# GD32E50x_CL register map
File version: 1.0
CPU: CM33 r0p4, little endian, MPU, FPU, 4 interrupt priority bits
Registers are 32-bit, read-write, reset 0x0 unless marked. A register's access mark holds for its fields unless they carry their own. Offsets are from the block's base; [hi:lo] are bit positions; {n}, {i} and the like mark numbered series.

## SHRTIMER_COMMON — SHRTIMER Common registers
Base 0x40017780
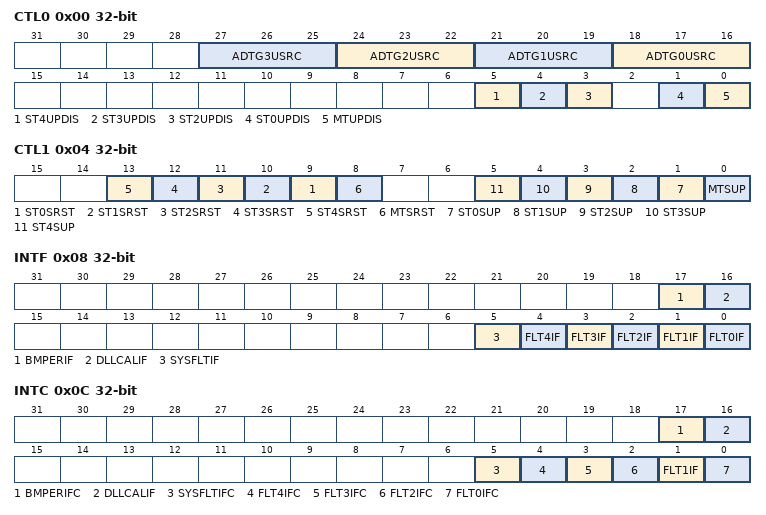
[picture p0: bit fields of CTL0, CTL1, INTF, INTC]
0x00 CTL0 — SHRTIMER control register 0
  [3n+18:3n+16] ADTG{n}USRC (n=0..3) — SHRTIMER_ADCTRIG{n} update source
  [5] ST4UPDIS — Slave_TIMER4 update disable
  [4] ST3UPDIS — Slave_TIMER3 update disable
  [3] ST2UPDIS — Slave_TIMER2 update disable
  [1] ST0UPDIS — Slave_TIMER0 update disable
  [0] MTUPDIS — Master_TIMER update disable
0x04 CTL1 — SHRTIMER control register 1
  [n+9] ST{n}SRST (n=0..4) — Slave_TIMER{n} software reset
  [8] MTSRST — Master_TIMER software reset
  [n+1] ST{n}SUP (n=0..4) — Slave_TIMER{n} software update
  [0] MTSUP — Master_TIMER software update
0x08 INTF ro — SHRTIMER interrupt flag register
  [17] BMPERIF — Bunch mode period interrupt flag
  [16] DLLCALIF — DLL calibration completed interrupt flag
  [5] SYSFLTIF — System fault interrupt flag
  [n] FLT{n}IF (n=0..4) — Fault {n} interrupt flag
0x0C INTC wo — SHRTIMER interrupt flag clear register
  [17] BMPERIFC — Clear bunch mode period interrupt flag
  [16] DLLCALIF — Clear DLL calibration completed interrupt flag
  [5] SYSFLTIFC — Clear system fault interrupt flag
  [4] FLT4IFC — Clear fault 4 interrupt flag
  [3] FLT3IFC — Clear fault 3 interrupt flag
  [2] FLT2IFC — Clear fault 2 interrupt flag
  [1] FLT1IF — Fault 1 interrupt flag
  [0] FLT0IFC — Fault 0 interrupt flag
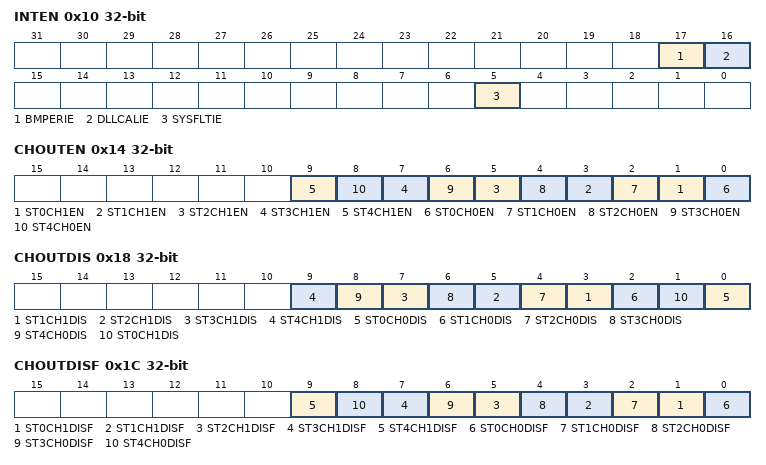
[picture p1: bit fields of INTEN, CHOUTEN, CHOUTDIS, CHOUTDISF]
0x10 INTEN — SHRTIMER interrupt enable register
  [17] BMPERIE — Bunch mode period interrupt enable
  [16] DLLCALIE — DLL calibration completed interrupt enable
  [5] SYSFLTIE — System fault interrupt enable
0x14 CHOUTEN — SHRTIMER channel output enable register
  [2n+1] ST{n}CH1EN (n=0..4) — Slave_TIMER{n} channel 1 output (ST{n}CH1_O) enable
  [2n] ST{n}CH0EN (n=0..4) — Slave_TIMER{n} channel 0 output (ST{n}CH0_O) enable
0x18 CHOUTDIS wo — SHRTIMER channel output disable register
  [2n+1] ST{n}CH1DIS (n=1..4) — Slave_TIMER{n} channel 1 output (ST{n}CH1_O) disable
  [2n] ST{n}CH0DIS (n=0..4) — Slave_TIMER{n} channel 0 output (ST{n}CH0_O) disable
  [1] ST0CH1DIS — Slave_TIMER0 channel 1 output (ST4CH0_O) disable
0x1C CHOUTDISF ro — SHRTIMER channel output disable flag register
  [2n+1] ST{n}CH1DISF (n=0..4) — Slave_TIMER{n} channel 1 output (ST{n}CH1_O) disable flag
  [2n] ST{n}CH0DISF (n=0..4) — Slave_TIMER{n} channel 0 output (ST{n}CH0_O) disable flag
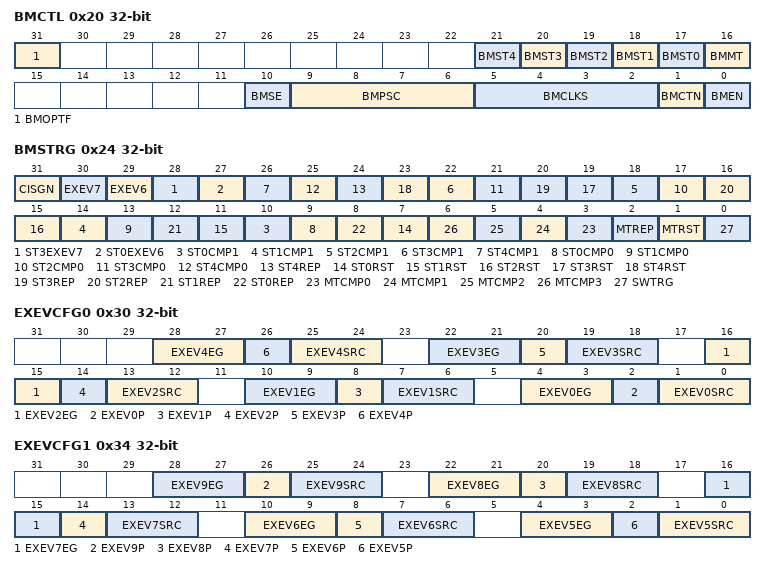
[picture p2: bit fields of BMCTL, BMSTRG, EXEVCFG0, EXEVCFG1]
0x20 BMCTL — SHRTIMER bunch mode control register
  [31] BMOPTF — Bunch mode operating flag
  [n+17] BMST{n} (n=0..4) — Slave_TIMER{n} bunch mode
  [16] BMMT — Master_TIMER bunch mode
  [10] BMSE — Bunch mode shadow enable
  [9:6] BMPSC — Bunch mode clock division
  [5:2] BMCLKS — Bunch mode clock source
  [1] BMCTN — Continuous mode in bunch mode
  [0] BMEN — Bunch mode enable
0x24 BMSTRG — SHRTIMER bunch mode start trigger register
  [31] CISGN — Chip internal signal triggers bunch mode operation
  [30] EXEV7 — External event 7 triggers bunch mode operation
  [29] EXEV6 — External event 6 triggers bunch mode operation
  [28] ST3EXEV7 — Slave_TIMER3 period event following external event 7 triggers bunch mode operation
  [27] ST0EXEV6 — Slave_TIMER0 period event following external event 6 triggers bunch mode operation
  [4n+10] ST{n}CMP1 (n=0..4) — Slave_TIMER{n} compare 1 event triggers bunch mode operation
  [4n+9] ST{n}CMP0 (n=0..4) — Slave_TIMER{n} compare 0 event triggers bunch mode operation
  [24] ST4REP — Slave_TIMER4 repetition event triggers bunch mode operation
  [4n+7] ST{n}RST (n=0..4) — Slave_TIMER{n} reset event triggers bunch mode operation
  [20] ST3REP — Slave_TIMER3 repetition event triggers bunch mode operation
  [16] ST2REP — Slave_TIMER1 repetition event triggers bunch mode operation
  [12] ST1REP — Slave_TIMER1 repetition event triggers bunch mode operation
  [8] ST0REP — Slave_TIMER0 repetition event triggers bunch mode operation
  [n+3] MTCMP{n} (n=0..3) — Master_TIMER compare {n} event triggers bunch mode operation
  [2] MTREP — Master_TIMER repetition event triggers bunch mode operation
  [1] MTRST — Master_TIMER reset event triggers bunch mode operation
  [0] SWTRG — Software triggers bunch mode operation
0x28 BMCMPV — SHRTIMER bunch mode compare value register
  [15:0] BMCMPVAL — Bunch mode compare value
0x2C BMCAR — SHRTIMER bunch mode counter auto reload register
  [15:0] BMCARL — Bunch mode counter auto reload value
0x30 EXEVCFG0 — SHRTIMER external event configuration register 0
  [6n+4:6n+3] EXEV{n}EG (n=0..4) — External event {n} edge sensitivity
  [6n+2] EXEV{n}P (n=0..4) — External event {n} polarity
  [6n+1:6n] EXEV{n}SRC (n=0..4) — External event {n} source
0x34 EXEVCFG1 — SHRTIMER external event configuration register 1
  [6n-26:6n-27] EXEV{n}EG (n=6..9) — External event {n} edge sensitivity
  [26] EXEV9P — External event 9 polarity
  [25:24] EXEV9SRC — External event 9 source
  [20] EXEV8P — External event 8 polarity
  [19:18] EXEV8SRC — External event 8 source
  [14] EXEV7P — External event 7polarity
  [13:12] EXEV7SRC — External event 7 source
  [8] EXEV6P — External event 1 polarity
  [7:6] EXEV6SRC — External event 1 source
  [4:3] EXEV5EG — External event 0 edge sensitivity
  [2] EXEV5P — External event 0 polarity
  [1:0] EXEV5SRC — External event 0 source
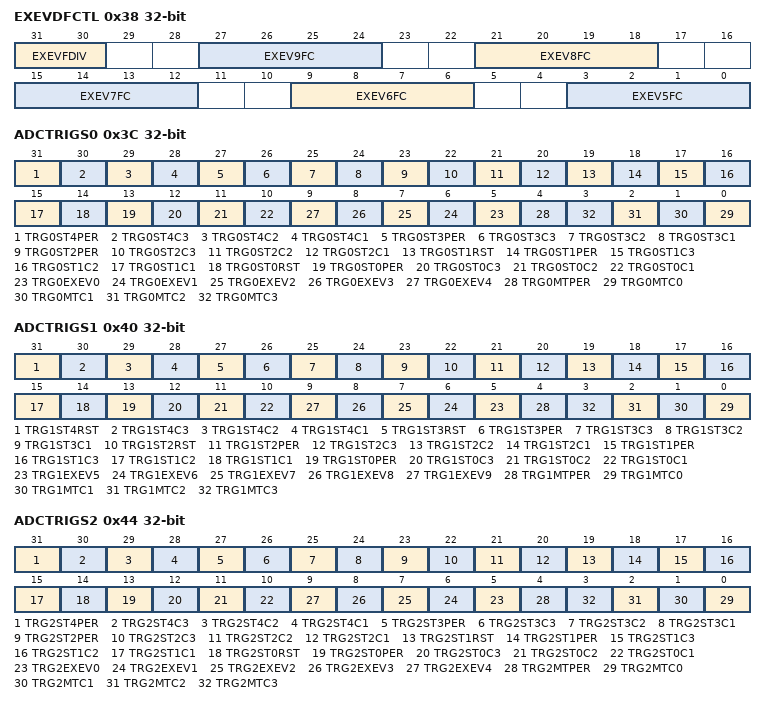
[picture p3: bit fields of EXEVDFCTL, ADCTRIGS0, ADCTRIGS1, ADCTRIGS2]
0x38 EXEVDFCTL — SHRTIMER external event digital filter control register
  [31:30] EXEVFDIV — External event digital filter clock division
  [6n-27:6n-30] EXEV{n}FC (n=5..9) — External event {n} filter control
0x3C ADCTRIGS0 — SHRTIMER trigger source 0 to ADC register
  [31] TRG0ST4PER — SHRTIMER_ADCTRIG0 on Slave_TIMER4 period event
  [30] TRG0ST4C3 — SHRTIMER_ADCTRIG0 on Slave_TIMER4 compare 3 event
  [29] TRG0ST4C2 — SHRTIMER_ADCTRIG0 on Slave_TIMER4 compare 2 event
  [28] TRG0ST4C1 — SHRTIMER_ADCTRIG0 on Slave_TIMER4 compare 1 event
  [27] TRG0ST3PER — SHRTIMER_ADCTRIG0 on Slave_TIMER3 period event
  [26] TRG0ST3C3 — SHRTIMER_ADCTRIG0 on Slave_TIMER3 compare 3 event
  [25] TRG0ST3C2 — SHRTIMER_ADCTRIG0 on Slave_TIMER3 compare 2 event
  [24] TRG0ST3C1 — SHRTIMER_ADCTRIG0 on Slave_TIMER3 compare 1 event
  [23] TRG0ST2PER — SHRTIMER_ADCTRIG0 on Slave_TIMER2 period event
  [22] TRG0ST2C3 — SHRTIMER_ADCTRIG0 on Slave_TIMER2 compare 3 event
  [21] TRG0ST2C2 — SHRTIMER_ADCTRIG0 on Slave_TIMER2 compare 2 event
  [20] TRG0ST2C1 — SHRTIMER_ADCTRIG0 on Slave_TIMER2 compare 1 event
  [19] TRG0ST1RST — SHRTIMER_ADCTRIG0 on Slave_TIMER1 reset
  [18] TRG0ST1PER — SHRTIMER_ADCTRIG0 on Slave_TIMER1 period event
  [17] TRG0ST1C3 — SHRTIMER_ADCTRIG0 on Slave_TIMER1 compare 3 event
  [16] TRG0ST1C2 — SHRTIMER_ADCTRIG0 on Slave_TIMER1 compare 2 event
  [15] TRG0ST1C1 — SHRTIMER_ADCTRIG0 on Slave_TIMER1 compare 1 event
  [14] TRG0ST0RST — SHRTIMER_ADCTRIG0 on Slave_TIMER0 reset
  [13] TRG0ST0PER — SHRTIMER_ADCTRIG0 on Slave_TIMER0 period event
  [12] TRG0ST0C3 — SHRTIMER_ADCTRIG0 on Slave_TIMER0 compare 3 event
  [11] TRG0ST0C2 — SHRTIMER_ADCTRIG0 on Slave_TIMER0 compare 2 event
  [10] TRG0ST0C1 — SHRTIMER_ADCTRIG0 on Slave_TIMER0 compare 1 event
  [n+5] TRG0EXEV{n} (n=0..4) — SHRTIMER_ADCTRIG0 on external event {n}
  [4] TRG0MTPER — SHRTIMER_ADCTRIG0 on Master_TIMER period event
  [n] TRG0MTC{n} (n=0..3) — SHRTIMER_ADCTRIG0 on Master_TIMER compare {n} event
0x40 ADCTRIGS1 — SHRTIMER trigger source 1 to ADC register
  [31] TRG1ST4RST — SHRTIMER_ADCTRIG1 on Slave_TIMER4 reset
  [30] TRG1ST4C3 — SHRTIMER_ADCTRIG1 on Slave_TIMER4 compare 3 event
  [29] TRG1ST4C2 — SHRTIMER_ADCTRIG1 on Slave_TIMER4 compare 2 event
  [28] TRG1ST4C1 — SHRTIMER_ADCTRIG1 on Slave_TIMER4 compare 1 event
  [27] TRG1ST3RST — SHRTIMER_ADCTRIG1 on Slave_TIMER3 reset
  [26] TRG1ST3PER — SHRTIMER_ADCTRIG1 on Slave_TIMER3 period event
  [25] TRG1ST3C3 — SHRTIMER_ADCTRIG1 on Slave_TIMER3 compare 3 event
  [24] TRG1ST3C2 — SHRTIMER_ADCTRIG1 on Slave_TIMER3 compare 2 event
  [23] TRG1ST3C1 — SHRTIMER_ADCTRIG1 on Slave_TIMER3 compare 1 event
  [22] TRG1ST2RST — SHRTIMER_ADCTRIG1 on Slave_TIMER2 reset
  [21] TRG1ST2PER — SHRTIMER_ADCTRIG1 on Slave_TIMER2 period event
  [20] TRG1ST2C3 — SHRTIMER_ADCTRIG1 on Slave_TIMER2 compare 3 event
  [19] TRG1ST2C2 — SHRTIMER_ADCTRIG1 on Slave_TIMER2 compare 2 event
  [18] TRG1ST2C1 — SHRTIMER_ADCTRIG1 on Slave_TIMER2 compare 1 event
  [17] TRG1ST1PER — SHRTIMER_ADCTRIG1 on Slave_TIMER1 period event
  [16] TRG1ST1C3 — SHRTIMER_ADCTRIG1 on Slave_TIMER1 compare 3 event
  [15] TRG1ST1C2 — SHRTIMER_ADCTRIG1 on Slave_TIMER1 compare 2 event
  [14] TRG1ST1C1 — SHRTIMER_ADCTRIG1 on Slave_TIMER1 compare 1 event
  [13] TRG1ST0PER — SHRTIMER_ADCTRIG1 on Slave_TIMER0 period event
  [12] TRG1ST0C3 — SHRTIMER_ADCTRIG1 on Slave_TIMER0 compare 3 event
  [11] TRG1ST0C2 — SHRTIMER_ADCTRIG1 on Slave_TIMER0 compare 2 event
  [10] TRG1ST0C1 — SHRTIMER_ADCTRIG1 on Slave_TIMER0 compare 1 event
  [n] TRG1EXEV{n} (n=5..9) — SHRTIMER_ADCTRIG1 on external event {n}
  [4] TRG1MTPER — SHRTIMER_ADCTRIG1 on Master_TIMER period event
  [n] TRG1MTC{n} (n=0..3) — SHRTIMER_ADCTRIG1 on Master_TIMER compare {n} event
0x44 ADCTRIGS2 — SHRTIMER trigger source 2 to ADC register
  [31] TRG2ST4PER — SHRTIMER_ADCTRIG2 on Slave_TIMER4 period event
  [30] TRG2ST4C3 — SHRTIMER_ADCTRIG2 on Slave_TIMER4 compare 3 event
  [29] TRG2ST4C2 — SHRTIMER_ADCTRIG2 on Slave_TIMER4 compare 2 event
  [28] TRG2ST4C1 — SHRTIMER_ADCTRIG2 on Slave_TIMER4 compare 1 event
  [27] TRG2ST3PER — SHRTIMER_ADCTRIG2 on Slave_TIMER3 period event
  [26] TRG2ST3C3 — SHRTIMER_ADCTRIG2 on Slave_TIMER3 compare 3 event
  [25] TRG2ST3C2 — SHRTIMER_ADCTRIG2 on Slave_TIMER3 compare 2 event
  [24] TRG2ST3C1 — SHRTIMER_ADCTRIG2 on Slave_TIMER3 compare 1 event
  [23] TRG2ST2PER — SHRTIMER_ADCTRIG2 on Slave_TIMER2 period event
  [22] TRG2ST2C3 — SHRTIMER_ADCTRIG2 on Slave_TIMER2 compare 3 event
  [21] TRG2ST2C2 — SHRTIMER_ADCTRIG2 on Slave_TIMER2 compare 2 event
  [20] TRG2ST2C1 — SHRTIMER_ADCTRIG2 on Slave_TIMER2 compare 1 event
  [19] TRG2ST1RST — SHRTIMER_ADCTRIG2 on Slave_TIMER1 reset
  [18] TRG2ST1PER — SHRTIMER_ADCTRIG2 on Slave_TIMER1 period event
  [17] TRG2ST1C3 — SHRTIMER_ADCTRIG2 on Slave_TIMER1 compare 3 event
  [16] TRG2ST1C2 — SHRTIMER_ADCTRIG2 on Slave_TIMER1 compare 2 event
  [15] TRG2ST1C1 — SHRTIMER_ADCTRIG2 on Slave_TIMER1 compare 1 event
  [14] TRG2ST0RST — SHRTIMER_ADCTRIG2 on Slave_TIMER0 reset
  [13] TRG2ST0PER — SHRTIMER_ADCTRIG2 on Slave_TIMER0 period event
  [12] TRG2ST0C3 — SHRTIMER_ADCTRIG2 on Slave_TIMER0 compare 3 event
  [11] TRG2ST0C2 — SHRTIMER_ADCTRIG2 on Slave_TIMER0 compare 2 event
  [10] TRG2ST0C1 — SHRTIMER_ADCTRIG2 on Slave_TIMER0 compare 1 event
  [n+5] TRG2EXEV{n} (n=0..4) — SHRTIMER_ADCTRIG2 on external event {n}
  [4] TRG2MTPER — SHRTIMER_ADCTRIG2 on Master_TIMER period event
  [n] TRG2MTC{n} (n=0..3) — SHRTIMER_ADCTRIG2 on Master_TIMER compare {n} event
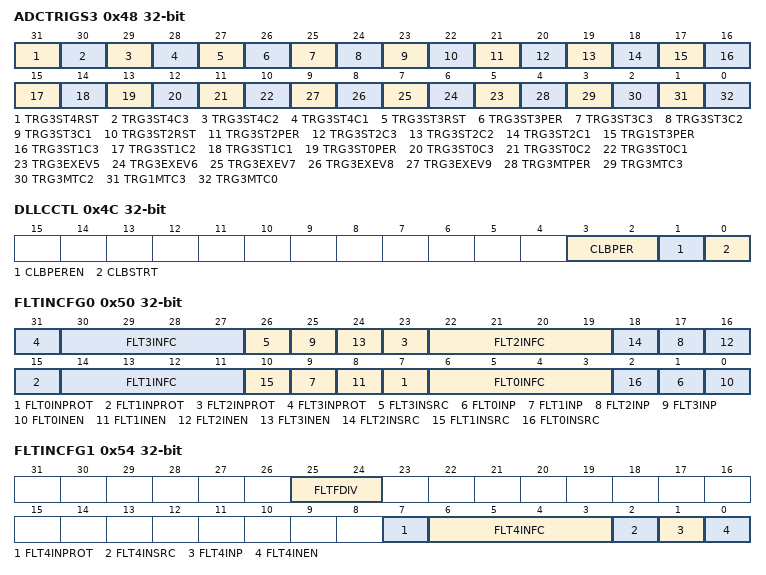
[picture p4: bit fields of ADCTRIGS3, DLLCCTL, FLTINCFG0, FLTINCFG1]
0x48 ADCTRIGS3 — SHRTIMER trigger source 3 to ADC register
  [31] TRG3ST4RST — SHRTIMER_ADCTRIG3 on Slave_TIMER4 reset
  [30] TRG3ST4C3 — SHRTIMER_ADCTRIG3 on Slave_TIMER4 compare 3 event
  [29] TRG3ST4C2 — SHRTIMER_ADCTRIG3 on Slave_TIMER4 compare 2 event
  [28] TRG3ST4C1 — SHRTIMER_ADCTRIG3 on Slave_TIMER4 compare 1 event
  [27] TRG3ST3RST — SHRTIMER_ADCTRIG3 on Slave_TIMER3 reset
  [26] TRG3ST3PER — SHRTIMER_ADCTRIG3 on Slave_TIMER3 period event
  [25] TRG3ST3C3 — SHRTIMER_ADCTRIG3 on Slave_TIMER3 compare 3 event
  [24] TRG3ST3C2 — SHRTIMER_ADCTRIG3 on Slave_TIMER3 compare 2 event
  [23] TRG3ST3C1 — SHRTIMER_ADCTRIG3 on Slave_TIMER3 compare 1 event
  [22] TRG3ST2RST — SHRTIMER_ADCTRIG3 on Slave_TIMER2 reset
  [21] TRG3ST2PER — SHRTIMER_ADCTRIG3 on Slave_TIMER2 period event
  [20] TRG3ST2C3 — SHRTIMER_ADCTRIG3 on Slave_TIMER2 compare 3 event
  [19] TRG3ST2C2 — SHRTIMER_ADCTRIG3 on Slave_TIMER2 compare 2 event
  [18] TRG3ST2C1 — SHRTIMER_ADCTRIG3 on Slave_TIMER2 compare 1 event
  [17] TRG1ST3PER — SHRTIMER_ADCTRIG3 on Slave_TIMER1 period event
  [16] TRG3ST1C3 — SHRTIMER_ADCTRIG3 on Slave_TIMER1 compare 3 event
  [15] TRG3ST1C2 — SHRTIMER_ADCTRIG3 on Slave_TIMER1 compare 2 event
  [14] TRG3ST1C1 — SHRTIMER_ADCTRIG3 on Slave_TIMER1 compare 1 event
  [13] TRG3ST0PER — SHRTIMER_ADCTRIG3 on Slave_TIMER0 period event
  [12] TRG3ST0C3 — SHRTIMER_ADCTRIG3 on Slave_TIMER0 compare 3 event
  [11] TRG3ST0C2 — SHRTIMER_ADCTRIG3 on Slave_TIMER0 compare 2 event
  [10] TRG3ST0C1 — SHRTIMER_ADCTRIG3 on Slave_TIMER0 compare 1 event
  [n] TRG3EXEV{n} (n=5..9) — SHRTIMER_ADCTRIG3 on external event {n}
  [4] TRG3MTPER — SHRTIMER_ADCTRIG3 on Master_TIMER period event
  [3] TRG3MTC3 — SHRTIMER_ADCTRIG3 on Master_TIMER compare 3 event
  [2] TRG3MTC2 — SHRTIMER_ADCTRIG3 on Master_TIMER compare 2 event
  [1] TRG1MTC3 — SHRTIMER_ADCTRIG3 on Master_TIMER compare 1 event
  [0] TRG3MTC0 — SHRTIMER_ADCTRIG3 on Master_TIMER compare 0 event
0x4C DLLCCTL — SHRTIMER DLL calibration control register
  [3:2] CLBPER — DLL calibration period
  [1] CLBPEREN — DLL periodic calibration enable
  [0] CLBSTRT — DLL calibration start once
0x50 FLTINCFG0 — SHRTIMER fault input configuration register 0
  [8n+7] FLT{n}INPROT (n=0..3) — Protect fault {n} input configuration
  [8n+6:8n+3] FLT{n}INFC (n=0..3) — Fault {n} input filter control
  [26] FLT3INSRC — Fault 3 input source
  [8n+1] FLT{n}INP (n=0..3) — Fault {n} input polarity
  [8n] FLT{n}INEN (n=0..3) — Fault {n} input enable
  [18] FLT2INSRC — Fault 2 input source
  [10] FLT1INSRC — Fault 2 input source
  [2] FLT0INSRC — Fault 0 input source
0x54 FLTINCFG1 — SHRTIMER fault input configuration register 1
  [25:24] FLTFDIV — Fault input digital filter clock division
  [7] FLT4INPROT — Protect fault 4 input configuration
  [6:3] FLT4INFC — Fault 4 input filter control
  [2] FLT4INSRC — Fault 4 input source
  [1] FLT4INP — Fault 4 input polarity
  [0] FLT4INEN — Fault 4 input enable
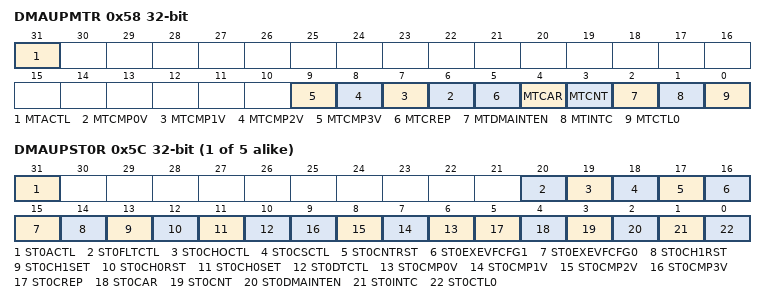
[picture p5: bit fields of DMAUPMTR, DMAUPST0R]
0x58 DMAUPMTR — SHRTIMER DMA update Master_TIMER register
  [31] MTACTL — SHRTIMER_MTACTL update by DMA mode
  [n+6] MTCMP{n}V (n=0..3) — SHRTIMER_MTCMP{n}V update by DMA mode
  [5] MTCREP — SHRTIMER_MTCAR update by DMA mode
  [4] MTCAR — SHRTIMER_MTCAR update by DMA mode
  [3] MTCNT — SHRTIMER_MTCNT update by DMA mode
  [2] MTDMAINTEN — SHRTIMER_MTDMAINTEN update by DMA mode
  [1] MTINTC — SHRTIMER_MTINTC update by DMA mode
  [0] MTCTL0 — SHRTIMER_MTCTL0 update by DMA mode
{0x5C+4i} DMAUPST{i}R (i=0..4) — SHRTIMER DMA update Slave_TIMER{i} register
  [31] ST{i}ACTL — SHRTIMER_ST{i}ACTL update by DMA mode
  [20] ST{i}FLTCTL — SHRTIMER_ST{i}FLTCTL update by DMA mode
  [19] ST{i}CHOCTL — SHRTIMER_ST{i}CHOCTL update by DMA mode
  [18] ST{i}CSCTL — SHRTIMER_ST{i}CSCTL update by DMA mode
  [17] ST{i}CNTRST — SHRTIMER_ST{i}CNTRST update by DMA mode
  [16] ST{i}EXEVFCFG1 — SHRTIMER_ST{i}EXEVFCFG1update by DMA mode
  [15] ST{i}EXEVFCFG0 — SHRTIMER_ST{i}EXEVFCFG0update by DMA mode
  [14] ST{i}CH1RST — SHRTIMER_ST{i}CH1RST update by DMA mode
  [13] ST{i}CH1SET — SHRTIMER_ST{i}CH1SET update by DMA mode
  [12] ST{i}CH0RST — SHRTIMER_ST{i}CH0RST update by DMA mode
  [11] ST{i}CH0SET — SHRTIMER_ST{i}CH0SET update by DMA mode
  [10] ST{i}DTCTL — SHRTIMER_ST{i}DTCTL update by DMA mode
  [n+6] ST{i}CMP{n}V (n=0..3) — SHRTIMER_ST{i}CMP{n}V update by DMA mode
  [5] ST{i}CREP — SHRTIMER_ST{i}CREP update by DMA mode
  [4] ST{i}CAR — SHRTIMER_ST{i}CAR update by DMA mode
  [3] ST{i}CNT — SHRTIMER_ST{i}CNT update by DMA mode
  [2] ST{i}DMAINTEN — SHRTIMER_ST{i}DMAINTEN update by DMA mode
  [1] ST{i}INTC — SHRTIMER_ST{i}INTC update by DMA mode
  [0] ST{i}CTL0 — SHRTIMER_ST{i}CTL0 update by DMA mode
0x70 DMATB wo — SHRTIMER DMA transfer buffer register
  [31:0] DMATB — DMA transfer buffer
